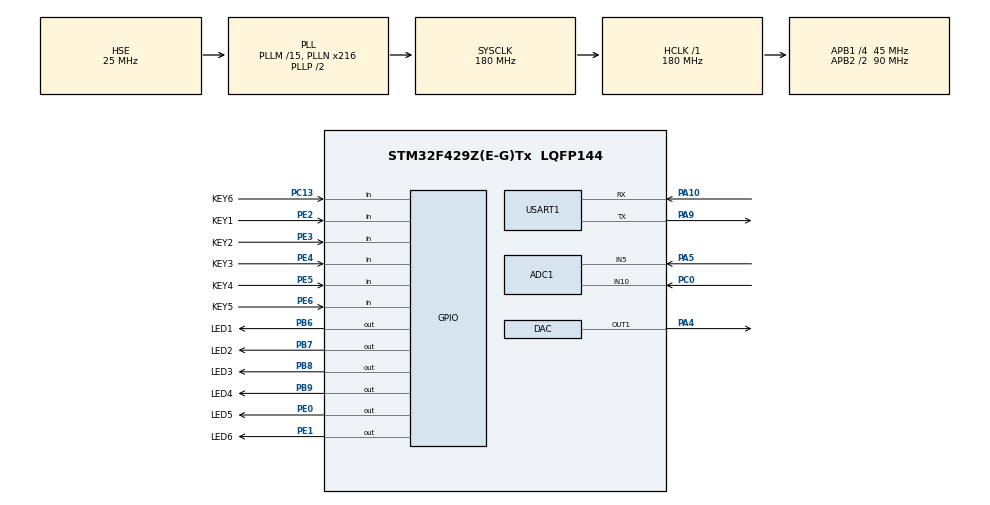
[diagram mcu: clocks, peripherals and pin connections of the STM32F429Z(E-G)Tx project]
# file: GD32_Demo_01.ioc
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ADC1.Channel-1\#ChannelRegularConversion=ADC_CHANNEL_10
ADC1.Channel-2\#ChannelRegularConversion=ADC_CHANNEL_5
ADC1.ContinuousConvMode=DISABLE
ADC1.DMAContinuousRequests=DISABLE
ADC1.ExternalTrigConv=ADC_EXTERNALTRIGCONV_T3_TRGO
ADC1.NbrOfConversion=2
ADC1.NbrOfConversionFlag=1
ADC1.Rank-1\#ChannelRegularConversion=1
ADC1.Rank-2\#ChannelRegularConversion=2
ADC1.SamplingTime-1\#ChannelRegularConversion=ADC_SAMPLETIME_3CYCLES
ADC1.SamplingTime-2\#ChannelRegularConversion=ADC_SAMPLETIME_3CYCLES
ADC1.ScanConvMode=ENABLE
ADC1.master=1
DAC.DAC_Trigger=DAC_TRIGGER_T6_TRGO
Dma.ADC1.1.Direction=DMA_PERIPH_TO_MEMORY
Dma.ADC1.1.FIFOMode=DMA_FIFOMODE_DISABLE
Dma.ADC1.1.Instance=DMA2_Stream0
Dma.ADC1.1.MemDataAlignment=DMA_MDATAALIGN_WORD
Dma.ADC1.1.MemInc=DMA_MINC_ENABLE
Dma.ADC1.1.Mode=DMA_NORMAL
Dma.ADC1.1.PeriphDataAlignment=DMA_PDATAALIGN_WORD
Dma.ADC1.1.PeriphInc=DMA_PINC_DISABLE
Dma.ADC1.1.Priority=DMA_PRIORITY_LOW
Dma.DAC1.2.Direction=DMA_MEMORY_TO_PERIPH
Dma.DAC1.2.FIFOMode=DMA_FIFOMODE_DISABLE
Dma.DAC1.2.Instance=DMA1_Stream5
Dma.DAC1.2.MemDataAlignment=DMA_MDATAALIGN_HALFWORD
Dma.DAC1.2.MemInc=DMA_MINC_ENABLE
Dma.DAC1.2.Mode=DMA_CIRCULAR
Dma.DAC1.2.PeriphDataAlignment=DMA_PDATAALIGN_HALFWORD
Dma.DAC1.2.PeriphInc=DMA_PINC_DISABLE
Dma.DAC1.2.Priority=DMA_PRIORITY_LOW
Dma.Request0=USART1_RX
Dma.Request1=ADC1
Dma.Request2=DAC1
Dma.USART1_RX.0.Direction=DMA_PERIPH_TO_MEMORY
Dma.USART1_RX.0.FIFOMode=DMA_FIFOMODE_DISABLE
Dma.USART1_RX.0.Instance=DMA2_Stream2
Dma.USART1_RX.0.MemDataAlignment=DMA_MDATAALIGN_BYTE
Dma.USART1_RX.0.MemInc=DMA_MINC_ENABLE
Dma.USART1_RX.0.Mode=DMA_NORMAL
Dma.USART1_RX.0.PeriphDataAlignment=DMA_PDATAALIGN_BYTE
Dma.USART1_RX.0.PeriphInc=DMA_PINC_DISABLE
Dma.USART1_RX.0.Priority=DMA_PRIORITY_LOW
Mcu.Family=STM32F4
Mcu.Name=STM32F429Z(E-G)Tx
Mcu.Package=LQFP144
NVIC.ADC_IRQn=true\:0\:0\:false\:false\:true\:true\:true\:true
NVIC.DMA1_Stream5_IRQn=true\:0\:0\:false\:false\:true\:false\:true\:true
NVIC.DMA2_Stream0_IRQn=true\:0\:0\:false\:false\:true\:false\:true\:true
NVIC.DMA2_Stream2_IRQn=true\:0\:0\:false\:false\:true\:false\:true\:true
NVIC.PriorityGroup=NVIC_PRIORITYGROUP_4
NVIC.USART1_IRQn=true\:0\:0\:false\:false\:true\:true\:true\:true
PA10.Mode=Asynchronous
PA10.Signal=USART1_RX
PA13.Mode=Serial_Wire
PA13.Signal=SYS_JTMS-SWDIO
PA14.Mode=Serial_Wire
PA14.Signal=SYS_JTCK-SWCLK
PA4.Signal=COMP_DAC1_group
PA5.Signal=ADCx_IN5
PA9.Mode=Asynchronous
PA9.Signal=USART1_TX
PB6.GPIO_Label=LED1
PB6.GPIO_ModeDefaultOutputPP=GPIO_MODE_OUTPUT_PP
PB6.GPIO_Speed=GPIO_SPEED_FREQ_LOW
PB6.PinState=GPIO_PIN_RESET
PB6.Signal=GPIO_Output
PB7.GPIO_Label=LED2
PB7.Signal=GPIO_Output
PB8.GPIO_Label=LED3
PB8.Signal=GPIO_Output
PB9.GPIO_Label=LED4
PB9.Signal=GPIO_Output
PC0.Signal=ADCx_IN10
PC13.GPIO_Label=KEY6
PC13.GPIO_PuPd=GPIO_PULLUP
PC13.Signal=GPIO_Input
PC14/OSC32_IN.Mode=LSE-External-Oscillator
PC14/OSC32_IN.Signal=RCC_OSC32_IN
PC15/OSC32_OUT.Mode=LSE-External-Oscillator
PC15/OSC32_OUT.Signal=RCC_OSC32_OUT
PE0.GPIO_Label=LED5
PE0.Signal=GPIO_Output
PE1.GPIO_Label=LED6
PE1.Signal=GPIO_Output
PE2.GPIO_Label=KEY1
PE2.GPIO_PuPd=GPIO_PULLUP
PE2.Signal=GPIO_Input
PE3.GPIO_Label=KEY2
PE3.GPIO_PuPd=GPIO_PULLUP
PE3.Signal=GPIO_Input
PE4.GPIO_Label=KEY3
PE4.GPIO_PuPd=GPIO_PULLUP
PE4.Signal=GPIO_Input
PE5.GPIO_Label=KEY4
PE5.GPIO_PuPd=GPIO_PULLUP
PE5.Signal=GPIO_Input
PE6.GPIO_Label=KEY5
PE6.GPIO_PuPd=GPIO_PULLUP
PE6.Signal=GPIO_Input
PH0/OSC_IN.Mode=HSE-External-Oscillator
PH0/OSC_IN.Signal=RCC_OSC_IN
PH1/OSC_OUT.Mode=HSE-External-Oscillator
PH1/OSC_OUT.Signal=RCC_OSC_OUT
ProjectManager.HeapSize=0x200
ProjectManager.StackSize=0x400
ProjectManager.TargetToolchain=MDK-ARM V5.32
RCC.48MHZClocksFreq_Value=90000000
RCC.AHBFreq_Value=180000000
RCC.APB1CLKDivider=RCC_HCLK_DIV4
RCC.APB1Freq_Value=45000000
RCC.APB1TimFreq_Value=90000000
RCC.APB2CLKDivider=RCC_HCLK_DIV2
RCC.APB2Freq_Value=90000000
RCC.APB2TimFreq_Value=180000000
RCC.CortexFreq_Value=180000000
RCC.HCLKFreq_Value=180000000
RCC.HSE_VALUE=25000000
RCC.HSI_VALUE=16000000
RCC.PLLM=15
RCC.PLLN=216
RCC.PLLSourceVirtual=RCC_PLLSOURCE_HSE
RCC.SYSCLKFreq_VALUE=180000000
RCC.SYSCLKSource=RCC_SYSCLKSOURCE_PLLCLK
RCC.VCOOutputFreq_Value=360000000
SH.ADCx_IN10.0=ADC1_IN10,IN10
SH.ADCx_IN5.0=ADC1_IN5,IN5
SH.COMP_DAC1_group.0=DAC_OUT1,DAC_OUT1
TIM3.Period=100-1
TIM3.Prescaler=90-1
TIM3.TIM_MasterOutputTrigger=TIM_TRGO_UPDATE
TIM6.Period=100-1
TIM6.Prescaler=90-1
TIM6.TIM_MasterOutputTrigger=TIM_TRGO_UPDATE
USART1.VirtualMode=VM_ASYNC
VP_TIM3_VS_ClockSourceINT.Mode=Internal
VP_TIM6_VS_ClockSourceINT.Mode=Enable_Timer
board=custom

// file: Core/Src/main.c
/* USER CODE BEGIN Header */
/**
  ******************************************************************************
  * @file           : main.c
  * @brief          : Main program body
  ******************************************************************************
  * @attention
  *
  * Copyright (c) 2025 STMicroelectronics.
  * All rights reserved.
  *
  * This software is licensed under terms that can be found in the LICENSE file
  * in the root directory of this software component.
  * If no LICENSE file comes with this software, it is provided AS-IS.
  *
  ******************************************************************************
  */
/* USER CODE END Header */
#include "main.h"
#include "adc.h"
#include "dac.h"
#include "dma.h"
#include "tim.h"
#include "usart.h"
#include "gpio.h"

/* USER CODE BEGIN Includes */
#include "scheduler.h"
/* USER CODE END Includes */

void SystemClock_Config(void);

int main(void)
{

  /* MCU Configuration--------------------------------------------------------*/

  /* Reset of all peripherals, Initializes the Flash interface and the Systick. */
  HAL_Init();

  /* Configure the system clock */
  SystemClock_Config();

  /* Initialize all configured peripherals */
  MX_GPIO_Init();
  MX_DMA_Init();
  MX_USART1_UART_Init();
  MX_ADC1_Init();
  MX_TIM3_Init();
  MX_DAC_Init();
  MX_TIM6_Init();
  /* USER CODE BEGIN 2 */
  /* 初始化软件调度器 */
  scheduler_init();
  /* 初始化按键事件库 */
  my_ebtn_init();
  /* 初始化串口 DMA + 空闲中断 + 环形缓冲区 */
  ringbuffer_init();
  /* 初始化波形控制参数并启动 DAC 波形输出 */
  wave_ctrl_init();
  /* 启动 TIM3 触发的 ADC DMA 采样 */
  adc_tim_dma_init();
  /* USER CODE END 2 */

  /* Infinite loop */
  while (1)
  {

    /* USER CODE BEGIN 3 */
    scheduler_run();
  }
  /* USER CODE END 3 */
}

void SystemClock_Config(void)
{
  RCC_OscInitTypeDef RCC_OscInitStruct = {0};
  RCC_ClkInitTypeDef RCC_ClkInitStruct = {0};

  /** Configure the main internal regulator output voltage
  */
  __HAL_RCC_PWR_CLK_ENABLE();
  __HAL_PWR_VOLTAGESCALING_CONFIG(PWR_REGULATOR_VOLTAGE_SCALE1);

  /** Initializes the RCC Oscillators according to the specified parameters
  * in the RCC_OscInitTypeDef structure.
  */
  RCC_OscInitStruct.OscillatorType = RCC_OSCILLATORTYPE_HSE;
  RCC_OscInitStruct.HSEState = RCC_HSE_ON;
  RCC_OscInitStruct.PLL.PLLState = RCC_PLL_ON;
  RCC_OscInitStruct.PLL.PLLSource = RCC_PLLSOURCE_HSE;
  RCC_OscInitStruct.PLL.PLLM = 15;
  RCC_OscInitStruct.PLL.PLLN = 216;
  RCC_OscInitStruct.PLL.PLLP = RCC_PLLP_DIV2;
  RCC_OscInitStruct.PLL.PLLQ = 4;
  if (HAL_RCC_OscConfig(&RCC_OscInitStruct) != HAL_OK)
  {
    Error_Handler();
  }

  /** Activate the Over-Drive mode
  */
  if (HAL_PWREx_EnableOverDrive() != HAL_OK)
  {
    Error_Handler();
  }

  /** Initializes the CPU, AHB and APB buses clocks
  */
  RCC_ClkInitStruct.ClockType = RCC_CLOCKTYPE_HCLK|RCC_CLOCKTYPE_SYSCLK
                              |RCC_CLOCKTYPE_PCLK1|RCC_CLOCKTYPE_PCLK2;
  RCC_ClkInitStruct.SYSCLKSource = RCC_SYSCLKSOURCE_PLLCLK;
  RCC_ClkInitStruct.AHBCLKDivider = RCC_SYSCLK_DIV1;
  RCC_ClkInitStruct.APB1CLKDivider = RCC_HCLK_DIV4;
  RCC_ClkInitStruct.APB2CLKDivider = RCC_HCLK_DIV2;

  if (HAL_RCC_ClockConfig(&RCC_ClkInitStruct, FLASH_LATENCY_5) != HAL_OK)
  {
    Error_Handler();
  }
}

void Error_Handler(void)
{
  __disable_irq();
  while (1)
  {
  }
}
